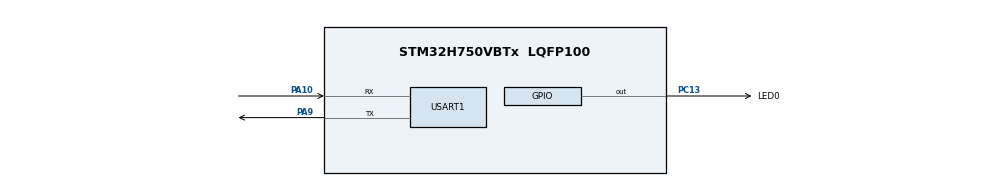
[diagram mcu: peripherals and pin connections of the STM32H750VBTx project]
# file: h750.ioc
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FREERTOS.Tasks01=defaultTask,0,512,StartDefaultTask,Default,NULL,Dynamic,NULL,NULL
Mcu.Family=STM32H7
Mcu.Name=STM32H750VBTx
Mcu.Package=LQFP100
NVIC.PriorityGroup=NVIC_PRIORITYGROUP_4
NVIC.TIM6_DAC_IRQn=true\:0\:0\:false\:false\:true\:false\:false\:true
NVIC.TimeBase=TIM6_DAC_IRQn
NVIC.TimeBaseIP=TIM6
NVIC.USART1_IRQn=true\:5\:0\:false\:false\:true\:true\:true\:true
PA10.Mode=Asynchronous
PA10.Signal=USART1_RX
PA13\ (JTMS/SWDIO).Mode=Serial_Wire
PA13\ (JTMS/SWDIO).Signal=DEBUG_JTMS-SWDIO
PA14\ (JTCK/SWCLK).Mode=Serial_Wire
PA14\ (JTCK/SWCLK).Signal=DEBUG_JTCK-SWCLK
PA9.Mode=Asynchronous
PA9.Signal=USART1_TX
PC13.GPIO_Label=LED0
PC13.Signal=GPIO_Output
PH0-OSC_IN\ (PH0).Mode=HSE-External-Oscillator
PH0-OSC_IN\ (PH0).Signal=RCC_OSC_IN
PH1-OSC_OUT\ (PH1).Mode=HSE-External-Oscillator
PH1-OSC_OUT\ (PH1).Signal=RCC_OSC_OUT
ProjectManager.HeapSize=0x2200
ProjectManager.StackSize=0x2400
ProjectManager.TargetToolchain=Makefile
RCC.ADCFreq_Value=96000000
RCC.APB1Freq_Value=120000000
RCC.APB2Freq_Value=120000000
RCC.APB3Freq_Value=120000000
RCC.APB4Freq_Value=120000000
RCC.CortexFreq_Value=480000000
RCC.D1PPRE=RCC_APB3_DIV2
RCC.D2PPRE1=RCC_APB1_DIV2
RCC.D2PPRE2=RCC_APB2_DIV2
RCC.D3PPRE=RCC_APB4_DIV2
RCC.DIVM1=5
RCC.DIVM2=25
RCC.DIVM3=25
RCC.DIVN1=192
RCC.DIVN2=192
RCC.DIVN3=192
RCC.DIVQ2=4
RCC.DIVQ3=4
RCC.HCLKFreq_Value=240000000
RCC.HPRE=RCC_HCLK_DIV2
RCC.PLLSourceVirtual=RCC_PLLSOURCE_HSE
RCC.SYSCLKFreq_VALUE=480000000
RCC.SYSCLKSource=RCC_SYSCLKSOURCE_PLLCLK
RCC.USBCLockSelection=RCC_USBCLKSOURCE_PLL3
RCC.USBFreq_Value=48000000
USART1.VirtualMode-Asynchronous=VM_ASYNC
VP_FREERTOS_VS_CMSIS_V1.Mode=CMSIS_V1
VP_SYS_VS_tim6.Mode=TIM6
board=custom

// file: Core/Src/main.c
/* USER CODE BEGIN Header */
/**
  ******************************************************************************
  * @file           : main.c
  * @brief          : Main program body
  ******************************************************************************
  * @attention
  *
  * <h2><center>&copy; Copyright (c) 2021 STMicroelectronics.
  * All rights reserved.</center></h2>
  *
  * This software component is licensed by ST under BSD 3-Clause license,
  * the "License"; You may not use this file except in compliance with the
  * License. You may obtain a copy of the License at:
  *                        opensource.org/licenses/BSD-3-Clause
  *
  ******************************************************************************
  */
/* USER CODE END Header */
#include "main.h"
#include "cmsis_os.h"
#include "usart.h"
#include "gpio.h"

void SystemClock_Config(void);
void MX_FREERTOS_Init(void);

int main(void)
{

  /* MCU Configuration--------------------------------------------------------*/

  /* Reset of all peripherals, Initializes the Flash interface and the Systick. */
  HAL_Init();

  /* Configure the system clock */
  SystemClock_Config();

  /* Initialize all configured peripherals */
  MX_GPIO_Init();
  MX_USART1_UART_Init();

  /* Call init function for freertos objects (in freertos.c) */
  MX_FREERTOS_Init();
  /* Start scheduler */
  osKernelStart();

  /* We should never get here as control is now taken by the scheduler */
  /* Infinite loop */
    while (1)
    {

    /* USER CODE BEGIN 3 */
        HAL_Delay(200);
    }
  /* USER CODE END 3 */
}

void SystemClock_Config(void)
{
  RCC_OscInitTypeDef RCC_OscInitStruct = {0};
  RCC_ClkInitTypeDef RCC_ClkInitStruct = {0};
  RCC_PeriphCLKInitTypeDef PeriphClkInitStruct = {0};

  /** Supply configuration update enable
  */
  HAL_PWREx_ConfigSupply(PWR_LDO_SUPPLY);
  /** Configure the main internal regulator output voltage
  */
  __HAL_PWR_VOLTAGESCALING_CONFIG(PWR_REGULATOR_VOLTAGE_SCALE0);

  while(!__HAL_PWR_GET_FLAG(PWR_FLAG_VOSRDY)) {}
  /** Initializes the RCC Oscillators according to the specified parameters
  * in the RCC_OscInitTypeDef structure.
  */
  RCC_OscInitStruct.OscillatorType = RCC_OSCILLATORTYPE_HSE;
  RCC_OscInitStruct.HSEState = RCC_HSE_ON;
  RCC_OscInitStruct.PLL.PLLState = RCC_PLL_ON;
  RCC_OscInitStruct.PLL.PLLSource = RCC_PLLSOURCE_HSE;
  RCC_OscInitStruct.PLL.PLLM = 5;
  RCC_OscInitStruct.PLL.PLLN = 192;
  RCC_OscInitStruct.PLL.PLLP = 2;
  RCC_OscInitStruct.PLL.PLLQ = 2;
  RCC_OscInitStruct.PLL.PLLR = 2;
  RCC_OscInitStruct.PLL.PLLRGE = RCC_PLL1VCIRANGE_2;
  RCC_OscInitStruct.PLL.PLLVCOSEL = RCC_PLL1VCOWIDE;
  RCC_OscInitStruct.PLL.PLLFRACN = 0;
  if (HAL_RCC_OscConfig(&RCC_OscInitStruct) != HAL_OK)
  {
    Error_Handler();
  }
  /** Initializes the CPU, AHB and APB buses clocks
  */
  RCC_ClkInitStruct.ClockType = RCC_CLOCKTYPE_HCLK|RCC_CLOCKTYPE_SYSCLK
                              |RCC_CLOCKTYPE_PCLK1|RCC_CLOCKTYPE_PCLK2
                              |RCC_CLOCKTYPE_D3PCLK1|RCC_CLOCKTYPE_D1PCLK1;
  RCC_ClkInitStruct.SYSCLKSource = RCC_SYSCLKSOURCE_PLLCLK;
  RCC_ClkInitStruct.SYSCLKDivider = RCC_SYSCLK_DIV1;
  RCC_ClkInitStruct.AHBCLKDivider = RCC_HCLK_DIV2;
  RCC_ClkInitStruct.APB3CLKDivider = RCC_APB3_DIV2;
  RCC_ClkInitStruct.APB1CLKDivider = RCC_APB1_DIV2;
  RCC_ClkInitStruct.APB2CLKDivider = RCC_APB2_DIV2;
  RCC_ClkInitStruct.APB4CLKDivider = RCC_APB4_DIV2;

  if (HAL_RCC_ClockConfig(&RCC_ClkInitStruct, FLASH_LATENCY_4) != HAL_OK)
  {
    Error_Handler();
  }
  PeriphClkInitStruct.PeriphClockSelection = RCC_PERIPHCLK_USART1;
  PeriphClkInitStruct.Usart16ClockSelection = RCC_USART16CLKSOURCE_D2PCLK2;
  if (HAL_RCCEx_PeriphCLKConfig(&PeriphClkInitStruct) != HAL_OK)
  {
    Error_Handler();
  }
}

 /**
  * @brief  Period elapsed callback in non blocking mode
  * @note   This function is called  when TIM6 interrupt took place, inside
  * HAL_TIM_IRQHandler(). It makes a direct call to HAL_IncTick() to increment
  * a global variable "uwTick" used as application time base.
  * @param  htim : TIM handle
  * @retval None
  */
void HAL_TIM_PeriodElapsedCallback(TIM_HandleTypeDef *htim)
{
  if (htim->Instance == TIM6) {
    HAL_IncTick();
  }
}

void Error_Handler(void)
{
    __disable_irq();
    while (1)
    {
    }
}

/************************ (C) COPYRIGHT STMicroelectronics *****END OF FILE****/

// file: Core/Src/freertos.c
/* USER CODE BEGIN Header */
/**
  ******************************************************************************
  * File Name          : freertos.c
  * Description        : Code for freertos applications
  ******************************************************************************
  * @attention
  *
  * <h2><center>&copy; Copyright (c) 2021 STMicroelectronics.
  * All rights reserved.</center></h2>
  *
  * This software component is licensed by ST under Ultimate Liberty license
  * SLA0044, the "License"; You may not use this file except in compliance with
  * the License. You may obtain a copy of the License at:
  *                             www.st.com/SLA0044
  *
  ******************************************************************************
  */
/* USER CODE END Header */

#include "FreeRTOS.h"
#include "task.h"
#include "main.h"
#include "cmsis_os.h"

/* USER CODE BEGIN Includes */
#include "usart.h"
#include "stdio.h"
#include "test.h"
/* USER CODE END Includes */

/* USER CODE BEGIN PTD */
extern UART_HandleTypeDef huart1;
/* USER CODE END PTD */

/* USER CODE BEGIN PD */
long cnt=0;
/* USER CODE END PD */

osThreadId defaultTaskHandle;

void StartDefaultTask(void const *argument);

void MX_FREERTOS_Init(void); /* (MISRA C 2004 rule 8.1) */

/* GetIdleTaskMemory prototype (linked to static allocation support) */
void vApplicationGetIdleTaskMemory(StaticTask_t **ppxIdleTaskTCBBuffer, StackType_t **ppxIdleTaskStackBuffer, uint32_t *pulIdleTaskStackSize);

/* USER CODE BEGIN GET_IDLE_TASK_MEMORY */
static StaticTask_t xIdleTaskTCBBuffer;
static StackType_t xIdleStack[configMINIMAL_STACK_SIZE];

void vApplicationGetIdleTaskMemory(StaticTask_t **ppxIdleTaskTCBBuffer, StackType_t **ppxIdleTaskStackBuffer, uint32_t *pulIdleTaskStackSize)
{
    *ppxIdleTaskTCBBuffer = &xIdleTaskTCBBuffer;
    *ppxIdleTaskStackBuffer = &xIdleStack[0];
    *pulIdleTaskStackSize = configMINIMAL_STACK_SIZE;
    /* place for user code */
}
/* USER CODE END GET_IDLE_TASK_MEMORY */

void MX_FREERTOS_Init(void)
{

    /* Create the thread(s) */
    /* definition and creation of defaultTask */
    osThreadDef(defaultTask, StartDefaultTask, osPriorityNormal, 0, 512);
    defaultTaskHandle = osThreadCreate(osThread(defaultTask), NULL);

}

void StartDefaultTask(void const *argument)
{
    /* USER CODE BEGIN StartDefaultTask */
    /* Infinite loop */

    for (;;)
    {
        cnt++;
        HAL_GPIO_TogglePin(LED0_GPIO_Port, LED0_Pin);
        printf("%04xd\r\n", test_data[cnt]);
        if (cnt == 65536)
        {
            cnt = 0;
        }
        osDelay(100);
    }
    /* USER CODE END StartDefaultTask */
}

/************************ (C) COPYRIGHT STMicroelectronics *****END OF FILE****/
